# ESP32-S31 register map
Vendor: ESPRESSIF SYSTEMS (SHANGHAI) CO., LTD.; Series: ESP32 S-Series; File version: 1
CPU: RV32IMAFC r0p0, little endian, no MPU, FPU, 0 interrupt priority bits
Address unit: 32 bits
Registers are 32-bit, read-write, reset 0x0 unless marked. A register's access mark holds for its fields unless they carry their own. Offsets are from the block's base; [hi:lo] are bit positions.

## LP_AON_CLKRST — LP_AON_CLKRST Peripheral
Base 0x20701000
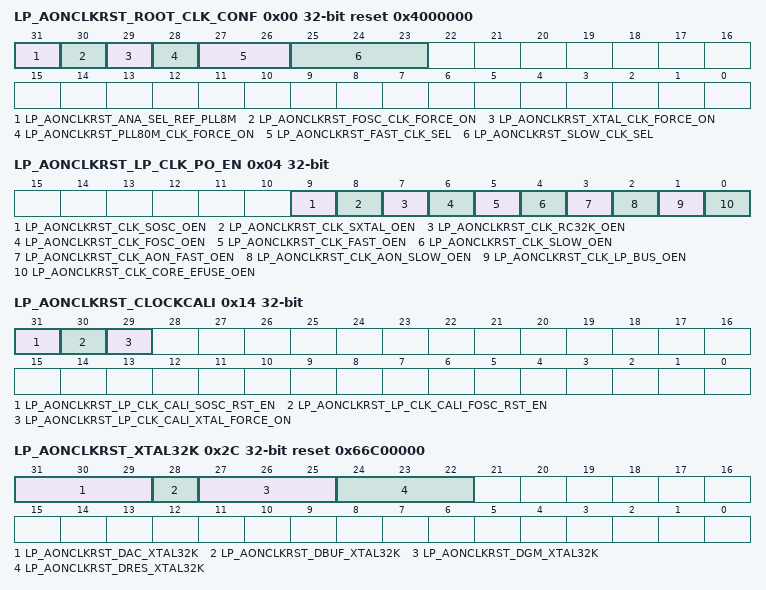
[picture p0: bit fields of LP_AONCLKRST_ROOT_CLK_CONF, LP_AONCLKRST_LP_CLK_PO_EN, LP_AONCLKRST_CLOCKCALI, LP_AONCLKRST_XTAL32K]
0x00 LP_AONCLKRST_ROOT_CLK_CONF reset 0x4000000 — need_des
  [31] LP_AONCLKRST_ANA_SEL_REF_PLL8M — need_des
  [30] LP_AONCLKRST_FOSC_CLK_FORCE_ON — need_des
  [29] LP_AONCLKRST_XTAL_CLK_FORCE_ON — need_des
  [28] LP_AONCLKRST_PLL80M_CLK_FORCE_ON — need_des
  [27:26] LP_AONCLKRST_FAST_CLK_SEL — need_des
  [25:23] LP_AONCLKRST_SLOW_CLK_SEL — need_des
0x04 LP_AONCLKRST_LP_CLK_PO_EN — need_des
  [9] LP_AONCLKRST_CLK_SOSC_OEN — 1'b1: probe sosc clk on 1'b0: probe sosc clk off
  [8] LP_AONCLKRST_CLK_SXTAL_OEN — need_des
  [7] LP_AONCLKRST_CLK_RC32K_OEN — need_des
  [6] LP_AONCLKRST_CLK_FOSC_OEN — need_des
  [5] LP_AONCLKRST_CLK_FAST_OEN — need_des
  [4] LP_AONCLKRST_CLK_SLOW_OEN — need_des
  [3] LP_AONCLKRST_CLK_AON_FAST_OEN — need_des
  [2] LP_AONCLKRST_CLK_AON_SLOW_OEN — need_des
  [1] LP_AONCLKRST_CLK_LP_BUS_OEN — need_des
  [0] LP_AONCLKRST_CLK_CORE_EFUSE_OEN — need_des
0x08 LP_AONCLKRST_MISC — need_des
  [31] LP_AONCLKRST_ETM_EVENT_TICK_EN
0x0C LP_AONCLKRST_TIMER — need_des
  [31] LP_AONCLKRST_LP_TIMER_RST_EN
0x10 LP_AONCLKRST_WDT — need_des
  [31] LP_AONCLKRST_LP_WDT_RST_EN
0x14 LP_AONCLKRST_CLOCKCALI — need_des
  [31] LP_AONCLKRST_LP_CLK_CALI_SOSC_RST_EN — need_des
  [30] LP_AONCLKRST_LP_CLK_CALI_FOSC_RST_EN — need_des
  [29] LP_AONCLKRST_LP_CLK_CALI_XTAL_FORCE_ON — need_des
0x18 LP_AONCLKRST_ANAPERI — need_des
  [31] LP_AONCLKRST_LP_ANAPERI_RST_EN
0x1C LP_AONCLKRST_HUK — need_des
  [31] LP_AONCLKRST_LP_HUK_RST_EN
0x20 LP_AONCLKRST_FOSC_DFREQ reset 0x41400000 — need_des
  [31:22] LP_AONCLKRST_FOSC_DFREQ
0x24 LP_AONCLKRST_RC32K_DFREQ reset 0x28A — need_des
0x28 LP_AONCLKRST_SOSC_DFREQ reset 0x2B000000 — need_des
  [31:22] LP_AONCLKRST_SOSC_DFREQ
0x2C LP_AONCLKRST_XTAL32K reset 0x66C00000 — need_des
  [31:29] LP_AONCLKRST_DAC_XTAL32K — need_des
  [28] LP_AONCLKRST_DBUF_XTAL32K — need_des
  [27:25] LP_AONCLKRST_DGM_XTAL32K — need_des
  [24:22] LP_AONCLKRST_DRES_XTAL32K — need_des
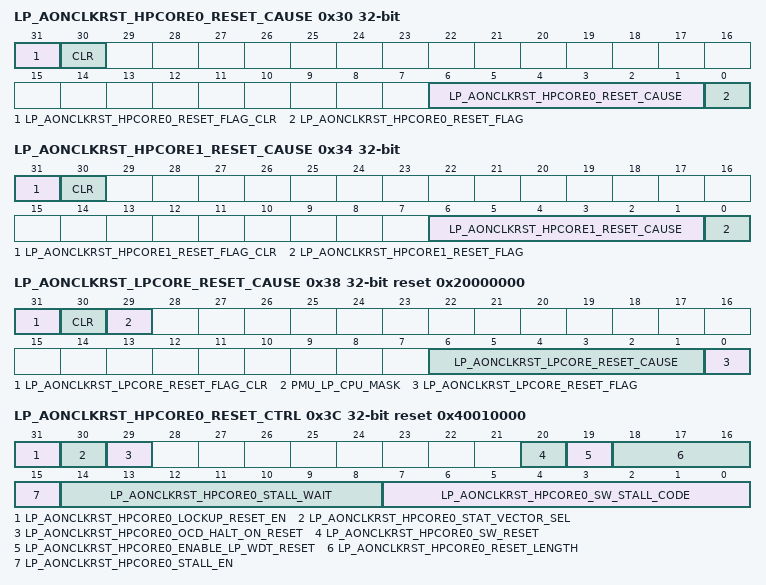
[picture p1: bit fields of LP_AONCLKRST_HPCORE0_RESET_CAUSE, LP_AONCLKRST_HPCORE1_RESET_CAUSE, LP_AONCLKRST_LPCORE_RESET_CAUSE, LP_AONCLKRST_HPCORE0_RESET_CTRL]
0x30 LP_AONCLKRST_HPCORE0_RESET_CAUSE access per field — need_des
  [31] LP_AONCLKRST_HPCORE0_RESET_FLAG_CLR wo — need_des
  [30] CLR wo — need_des
  [6:1] LP_AONCLKRST_HPCORE0_RESET_CAUSE ro — 6'h1: POR reset 6'h3: digital system software reset 6'h5: PMU HP system power down reset 6'h7: HP system reset from HP watchdog0 6'h8: HP system reset from HP watchdog1 6'h9: HP system reset from LP watchdog 6'hb: HP core reset from HP watchdog 6'hc: HP core software reset 6'hd: HP core reset from LP watchdog 6'hf: brown out reset 6'h10: LP watchdog chip reset 6'h12: super watch dog reset 6'h13: glitch reset 6'h14: efuse crc error reset 6'h16: HP usb jtag chip reset 6'h17: HP usb uart chip reset 6'h18: HP jtag reset 6'h1a: HP core lockup
  [0] LP_AONCLKRST_HPCORE0_RESET_FLAG ro — need_des
0x34 LP_AONCLKRST_HPCORE1_RESET_CAUSE access per field — need_des
  [31] LP_AONCLKRST_HPCORE1_RESET_FLAG_CLR wo — need_des
  [30] CLR wo — need_des
  [6:1] LP_AONCLKRST_HPCORE1_RESET_CAUSE ro — 6'h1: POR reset 6'h3: digital system software reset 6'h5: PMU HP system power down reset 6'h7: HP system reset from HP watchdog0 6'h8: HP system reset from HP watchdog1 6'h9: HP system reset from LP watchdog 6'hb: HP core reset from HP watchdog 6'hc: HP core software reset 6'hd: HP core reset from LP watchdog 6'hf: brown out reset 6'h10: LP watchdog chip reset 6'h12: super watch dog reset 6'h13: glitch reset 6'h14: efuse crc error reset 6'h16: HP usb jtag chip reset 6'h17: HP usb uart chip reset 6'h18: HP jtag reset 6'h1a: HP core lockup
  [0] LP_AONCLKRST_HPCORE1_RESET_FLAG ro — need_des
0x38 LP_AONCLKRST_LPCORE_RESET_CAUSE access per field reset 0x20000000 — need_des
  [31] LP_AONCLKRST_LPCORE_RESET_FLAG_CLR wo — need_des
  [30] CLR wo — need_des
  [29] PMU_LP_CPU_MASK rw — 1'b0: enable lpcore pmu_lp_cpu_reset reset_cause, 1'b1: disable lpcore pmu_lp_cpu_reset reset_cause
  [6:1] LP_AONCLKRST_LPCORE_RESET_CAUSE ro — 6'h1: POR reset 6'h9: PMU LP PERI power down reset 6'ha: PMU LP CPU reset 6'hf: brown out reset 6'h10: LP watchdog chip reset 6'h12: super watch dog reset 6'h13: glitch reset 6'h14: software reset
  [0] LP_AONCLKRST_LPCORE_RESET_FLAG ro — need_des
0x3C LP_AONCLKRST_HPCORE0_RESET_CTRL access per field reset 0x40010000 — need_des
  [31] LP_AONCLKRST_HPCORE0_LOCKUP_RESET_EN rw — write 1 to enable hpcore0 lockup reset feature, write 0 to disable hpcore0 lockup reset feature
  [30] LP_AONCLKRST_HPCORE0_STAT_VECTOR_SEL rw — 1'b1: boot from HP TCM ROM: 0x4FC00000 1'b0: boot from LP TCM RAM: 0x50108000
  [29] LP_AONCLKRST_HPCORE0_OCD_HALT_ON_RESET rw — need_des
  [20] LP_AONCLKRST_HPCORE0_SW_RESET wo — need_des
  [19] LP_AONCLKRST_HPCORE0_ENABLE_LP_WDT_RESET rw — write 1 to enable lp_wdt reset hpcore0 feature, write 0 to disable lp_wdt reset hpcore0 feature
  [18:16] LP_AONCLKRST_HPCORE0_RESET_LENGTH rw — need_des
  [15] LP_AONCLKRST_HPCORE0_STALL_EN rw — need_des
  [14:8] LP_AONCLKRST_HPCORE0_STALL_WAIT rw — need_des
  [7:0] LP_AONCLKRST_HPCORE0_SW_STALL_CODE rw — reserved
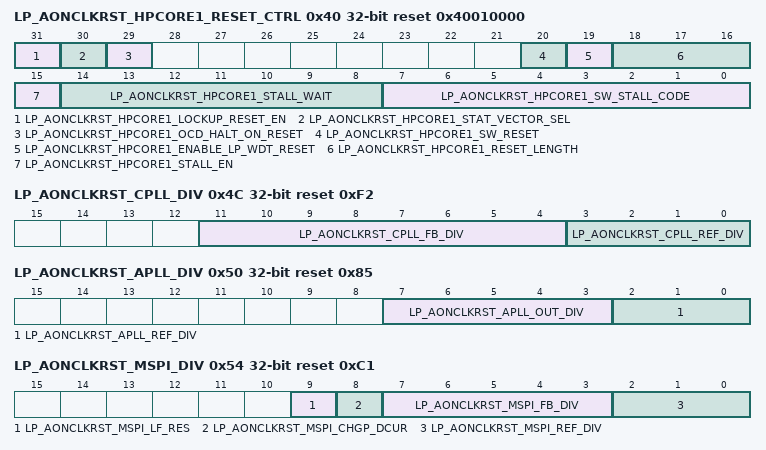
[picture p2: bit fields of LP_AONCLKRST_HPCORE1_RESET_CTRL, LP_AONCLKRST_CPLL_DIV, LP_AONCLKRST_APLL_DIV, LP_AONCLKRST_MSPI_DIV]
0x40 LP_AONCLKRST_HPCORE1_RESET_CTRL access per field reset 0x40010000 — need_des
  [31] LP_AONCLKRST_HPCORE1_LOCKUP_RESET_EN rw — write 1 to enable hpcore1 lockup reset feature, write 0 to disable hpcore1 lockup reset feature
  [30] LP_AONCLKRST_HPCORE1_STAT_VECTOR_SEL rw — 1'b1: boot from HP TCM ROM: 0x4FC00000 1'b0: boot from LP TCM RAM: 0x50108000
  [29] LP_AONCLKRST_HPCORE1_OCD_HALT_ON_RESET rw — need_des
  [20] LP_AONCLKRST_HPCORE1_SW_RESET wo — need_des
  [19] LP_AONCLKRST_HPCORE1_ENABLE_LP_WDT_RESET rw — write 1 to enable lp_wdt reset hpcore1 feature, write 0 to disable lp_wdt reset hpcore1 feature
  [18:16] LP_AONCLKRST_HPCORE1_RESET_LENGTH rw — need_des
  [15] LP_AONCLKRST_HPCORE1_STALL_EN rw — need_des
  [14:8] LP_AONCLKRST_HPCORE1_STALL_WAIT rw — need_des
  [7:0] LP_AONCLKRST_HPCORE1_SW_STALL_CODE rw — reserved
0x44 LP_AONCLKRST_TOUCH_AON — need_des
  [31] RST_EN
0x48 LP_AONCLKRST_HP_CLK_CTRL ro reset 0x28 — HP Clock Control Register.
  [6:0] LP_AONCLKRST_CLK_XTAL_FREQ — XTAL Clock Freq Indication. 7'd40: xtal_40m, 7'd48: xtal_48m
0x4C LP_AONCLKRST_CPLL_DIV reset 0xF2 — need_des
  [11:4] LP_AONCLKRST_CPLL_FB_DIV — cpll fb div value
  [3:0] LP_AONCLKRST_CPLL_REF_DIV — cpll ref div value
0x50 LP_AONCLKRST_APLL_DIV reset 0x85 — need_des
  [7:3] LP_AONCLKRST_APLL_OUT_DIV — apll out div value
  [2:0] LP_AONCLKRST_APLL_REF_DIV — apll ref div value
0x54 LP_AONCLKRST_MSPI_DIV reset 0xC1 — need_des
  [9] LP_AONCLKRST_MSPI_LF_RES — MSPI lf_res value
  [8] LP_AONCLKRST_MSPI_CHGP_DCUR — MSPI chgp_dcur value
  [7:3] LP_AONCLKRST_MSPI_FB_DIV — MSPI fb div value
  [2:0] LP_AONCLKRST_MSPI_REF_DIV — MSPI ref div value
0x58 LP_AONCLKRST_LP_ADI — need_des
  [31] RST_EN
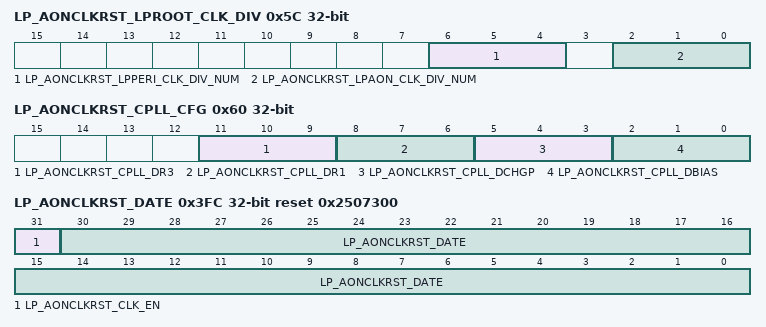
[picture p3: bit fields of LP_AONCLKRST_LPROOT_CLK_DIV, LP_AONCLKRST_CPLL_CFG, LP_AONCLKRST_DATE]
0x5C LP_AONCLKRST_LPROOT_CLK_DIV — need_des
  [6:4] LP_AONCLKRST_LPPERI_CLK_DIV_NUM — lp peri clock divide num
  [2:0] LP_AONCLKRST_LPAON_CLK_DIV_NUM — lp aon clock divide num
0x60 LP_AONCLKRST_CPLL_CFG — need_des
  [11:9] LP_AONCLKRST_CPLL_DR3 — cpll dr3 value
  [8:6] LP_AONCLKRST_CPLL_DR1 — cpll dr1 value
  [5:3] LP_AONCLKRST_CPLL_DCHGP — cpll dchgp value
  [2:0] LP_AONCLKRST_CPLL_DBIAS — cpll dbias value
0x64 LP_AONCLKRST_APLL_SDM — need_des
  [21:0] LP_AONCLKRST_APLL_SDM — apll sdm value
0x68 LP_AONCLKRST_RTC_SAR2_PWDET_CCT — need_des
  [2:0] LP_AONCLKRST_RTC_SAR2_PWDET_CCT — rtc_sar2_pwdet_cct value
0x3FC LP_AONCLKRST_DATE reset 0x2507300 — need_des
  [31] LP_AONCLKRST_CLK_EN — need_des
  [30:0] LP_AONCLKRST_DATE — need_des
